# SIM3U167_B register map
File version: 1
CPU: 
Registers are 32-bit, read-write, reset 0x0 unless marked. A register's access mark holds for its fields unless they carry their own. Offsets are from the block's base; [hi:lo] are bit positions; 'fields as' and 'values as' point back to an identical list.

## EMIF_0
Base 0x40026000
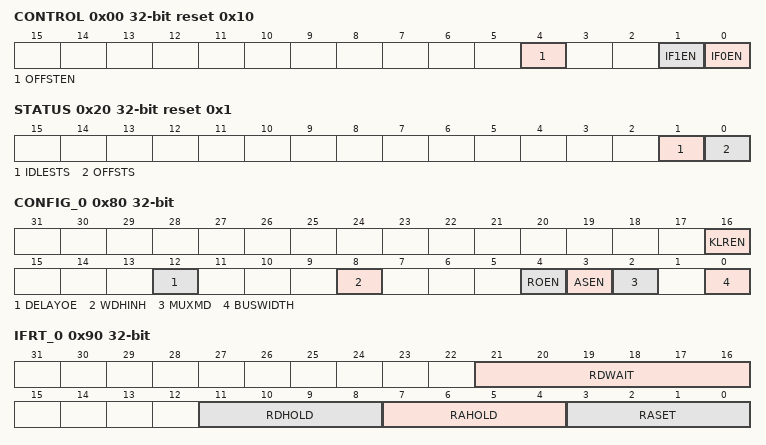
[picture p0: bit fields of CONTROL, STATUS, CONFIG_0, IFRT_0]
0x00 CONTROL reset 0x10 — Module Control
  [4] OFFSTEN — OFF Output State Enable.
    0=DISABLED (EMIF will not enter the off state after 4 idle cycles.); 1=ENABLED (EMIF will enter the off state after 4 idle cycles.)
  [1] IF1EN — Interface 1 Enable.
    0=DISABLED (Disable interface 1.); 1=ENABLED (Enable interface 1.)
  [0] IF0EN — Interface 0 Enable.
    0=DISABLED (Disable interface 0.); 1=ENABLED (Enable interface 0.)
0x20 STATUS reset 0x1 — Module Status
  [1] IDLESTS ro — EMIF IDLE Status.
    0=NOT_IDLE (The EMIF has not been idle for four cycles.); 1=IDLE (The EMIF has been idle for four four cycles.)
  [0] OFFSTS ro — EMIF OFF Status.
    0=ON (The EMIF bus is active.); 1=OFF (The EMIF is in the off bus state.)
0x80 CONFIG_0 — Interface Configuration
  [16] KLREN — Keep Last Read Enable.
    0=DISABLED (The bus is driven to the idle state between active requests.); 1=ENABLED (The bus drives the last value read on the interface between active requests.)
  [12] DELAYOE — Output Enable Delay.
    0=DISABLED (The output enable signal (/OE) is not delayed.); 1=ENABLED (The output enable signal (/OE) is delayed.)
  [8] WDHINH — Write Data Hold State Inhibit.
    0=INACTIVE (Enable the write data hold state.); 1=ACTIVE (Inhibit the write data hold state.)
  [4] ROEN — Interface Read Only Enable.
    0=DISABLED (The interface supports reads and writes.); 1=ENABLED (The interface supports only reads.)
  [3] ASEN — Interface Automatic Address Shift Enable.
    0=DISABLED (The address is not automatically shifted.); 1=ENABLED (The address is automatically shifted.)
  [2] MUXMD — Interface Mux Mode.
    0=NONMUXED (The interface operates in non-multiplexed mode.); 1=MUXED (The interface operates in multiplexed mode.)
  [0] BUSWIDTH — Interface Bus Data Width.
    0=8BIT (The data bus is 8-bits wide.); 1=16BIT (The data bus is 16-bits wide.)
0x90 IFRT_0 — Interface Read Timing
  [21:16] RDWAIT — Interface Read Data Wait Delay.
  [11:8] RDHOLD — Interface Read Data Hold Delay.
  [7:4] RAHOLD — Interface Read Address Hold Delay.
  [3:0] RASET — Interface Read Address Setup Delay .
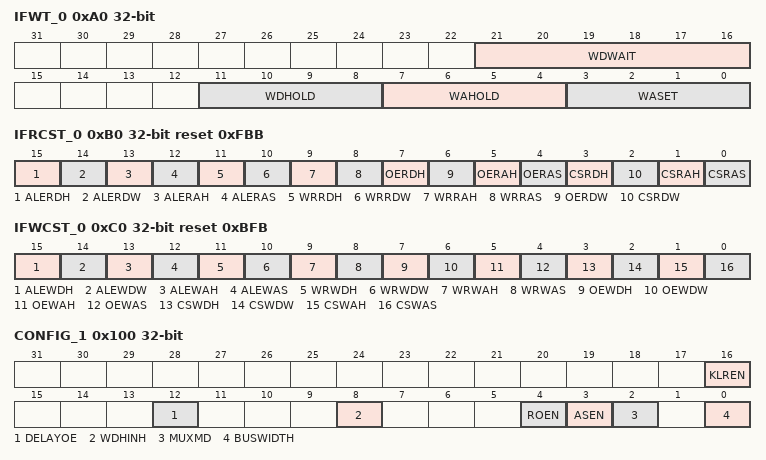
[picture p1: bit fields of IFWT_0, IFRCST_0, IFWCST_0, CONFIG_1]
0xA0 IFWT_0 — Interface Write Timing
  [21:16] WDWAIT — Interface Write Data Wait Delay.
  [11:8] WDHOLD — Interface Write Data Hold Delay.
  [7:4] WAHOLD — Interface Write Address Hold Delay.
  [3:0] WASET — Interface Write Address Setup Delay .
0xB0 IFRCST_0 reset 0xFBB — Interface Read Control States
  [15] ALERDH — Address Latch Enable Read Data Hold State.
    0=LOW (Set address latch enable (ALEm) to low during the read data hold state.); 1=HIGH (Set address latch enable (ALEm) to high during the read data hold state.)
  [14] ALERDW — Address Latch Enable Read Data Wait State.
    0=LOW (Set address latch enable (ALEm) to low during the read data wait state.); 1=HIGH (Set address latch enable (ALEm) to high during the read data wait state.)
  [13] ALERAH — Address Latch Enable Read Address Hold State.
    0=LOW (Set address latch enable (ALEm) to low during the read address hold state.); 1=HIGH (Set address latch enable (ALEm) to high during the read address hold state.)
  [12] ALERAS — Address Latch Enable Read Address Setup State.
    0=LOW (Set address latch enable (ALEm) to low during the read address setup state.); 1=HIGH (Set address latch enable (ALEm) to high during the read address setup state.)
  [11] WRRDH — Write Signal Read Data Hold State.
    0=LOW (Set write signal (/WR) to low during the read data hold state.); 1=HIGH (Set write signal (/WR) to high during the read data hold state.)
  [10] WRRDW — Write Signal Read Data Wait State.
    0=LOW (Set write signal (/WR) to low during the read data wait state.); 1=HIGH (Set write signal (/WR) to high during the read data wait state.)
  [9] WRRAH — Write Signal Read Address Hold State.
    0=LOW (Set write signal (/WR) to low during the read address hold state.); 1=HIGH (Set write signal (/WR) to high during the read address hold state.)
  [8] WRRAS — Write Signal Read Address Setup State.
    0=LOW (Set write signal (/WR) to low during the read address setup state.); 1=HIGH (Set write signal (/WR) to high during the read address setup state.)
  [7] OERDH — Output Enable Read Data Hold State.
    0=LOW (Set output enable (/OE) to low during the read data hold state.); 1=HIGH (Set output enable (/OE) to high during the read data hold state.)
  [6] OERDW — Output Enable Read Data Wait State.
    0=LOW (Set output enable (/OE) to low during the read data wait state.); 1=HIGH (Set output enable (/OE) to high during the read data wait state.)
  [5] OERAH — Output Enable Read Address Hold State.
    0=LOW (Set output enable (/OE) to low during the read address hold state.); 1=HIGH (Set output enable (/OE) to high during the read address hold state.)
  [4] OERAS — Output Enable Read Address Setup State.
    0=LOW (Set output enable (/OE) to low during the read address setup state.); 1=HIGH (Set output enable (/OE) to high during the read address setup state.)
  [3] CSRDH — Chip Select Read Data Hold State.
    0=LOW (Set chip select (CSx) to low during the read data hold state.); 1=HIGH (Set chip select (CSx) to high during the read data hold state.)
  [2] CSRDW — Chip Select Read Data Wait State.
    0=LOW (Set chip select (CSx) to low during the read data wait state.); 1=HIGH (Set chip select (CSx) to high during the read data wait state.)
  [1] CSRAH — Chip Select Read Address Hold State.
    0=LOW (Set chip select (CSx) to low during the read address hold state.); 1=HIGH (Set chip select (CSx) to high during the read address hold state.)
  [0] CSRAS — Chip Select Read Address Setup State.
    0=LOW (Set chip select (CSx) to low during the read address setup state.); 1=HIGH (Set chip select (CSx) to high during the read address setup state.)
0xC0 IFWCST_0 reset 0xBFB — Interface Write Control States
  [15] ALEWDH — Address Latch Enable Write Data Hold State.
    0=LOW (Set address latch enable (ALEm) to low during the write data hold state.); 1=HIGH (Set address latch enable (ALEm) to high during the write data hold state.)
  [14] ALEWDW — Address Latch Enable Write Data Wait State.
    0=LOW (Set address latch enable (ALEm) to low during the write data wait state.); 1=HIGH (Set address latch enable (ALEm) to high during the write data wait state.)
  [13] ALEWAH — Address Latch Enable Write Address Hold State.
    0=LOW (Set address latch enable (ALEm) to low during the write address hold state.); 1=HIGH (Set address latch enable (ALEm) to high during the write address hold state.)
  [12] ALEWAS — Address Latch Enable Write Address Setup State.
    0=LOW (Set address latch enable (ALEm) to low during the write address setup state.); 1=HIGH (Set address latch enable (ALEm) to high during the write address setup state.)
  [11] WRWDH — Write Signal Write Data Hold State.
    0=LOW (Set write signal (/WR) to low during the write data hold state.); 1=HIGH (Set write signal (/WR) to high during the write data hold state.)
  [10] WRWDW — Write Signal Write Data Wait State.
    0=LOW (Set write signal (/WR) to low during the write data wait state.); 1=HIGH (Set write signal (/WR) to high during the write data wait state.)
  [9] WRWAH — Write Signal Write Address Hold State.
    0=LOW (Set write signal (/WR) to low during the write address hold state.); 1=HIGH (Set write signal (/WR) to high during the write address hold state.)
  [8] WRWAS — Write Signal Write Address Setup State.
    0=LOW (Set write signal (/WR) to low during the write address setup state.); 1=HIGH (Set write signal (/WR) to high during the write address setup state.)
  [7] OEWDH — Output Enable Write Data Hold State.
    0=LOW (Set output enable (/OE) to low during the write data hold state.); 1=HIGH (Set output enable (/OE) to high during the write data hold state.)
  [6] OEWDW — Output Enable Write Data Wait State.
    0=LOW (Set output enable (/OE) to low during the write data wait state.); 1=HIGH (Set output enable (/OE) to high during the write data wait state.)
  [5] OEWAH — Output Enable Write Address Hold State.
    0=LOW (Set output enable (/OE) to low during the write address hold state.); 1=HIGH (Set output enable (/OE) to high during the write address hold state.)
  [4] OEWAS — Output Enable Write Address Setup State.
    0=LOW (Set output enable (/OE) to low during the write address setup state.); 1=HIGH (Set output enable (/OE) to high during the write address setup state.)
  [3] CSWDH — Chip Select Write Data Hold State.
    0=LOW (Set chip select (CSx) to low during the write data hold state.); 1=HIGH (Set chip select (CSx) to high during the write data hold state.)
  [2] CSWDW — Chip Select Write Data Wait State.
    0=LOW (Set chip select (CSx) to low during the write data wait state.); 1=HIGH (Set chip select (CSx) to high during the write data wait state.)
  [1] CSWAH — Chip Select Write Address Hold State.
    0=LOW (Set chip select (CSx) to low during the write address hold state.); 1=HIGH (Set chip select (CSx) to high during the write address hold state.)
  [0] CSWAS — Chip Select Write Address Setup State.
    0=LOW (Set chip select (CSx) to low during the write address setup state.); 1=HIGH (Set chip select (CSx) to high during the write address setup state.)
0x100 CONFIG_1 — Interface Configuration
  fields as CONFIG_0
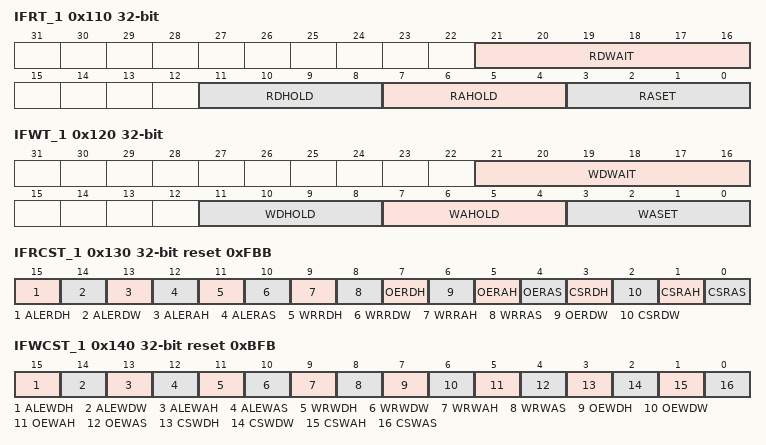
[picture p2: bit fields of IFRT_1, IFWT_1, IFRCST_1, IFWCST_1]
0x110 IFRT_1 — Interface Read Timing
  fields as IFRT_0
0x120 IFWT_1 — Interface Write Timing
  fields as IFWT_0
0x130 IFRCST_1 reset 0xFBB — Interface Read Control States
  fields as IFRCST_0
0x140 IFWCST_1 reset 0xBFB — Interface Write Control States
  fields as IFWCST_0
